# SN32F240 register map
Vendor: SONiX Technology Co., Ltd.; Series: SN32F200; File version: 2.0
CPU: CM0 r0p0, little endian, no MPU, no FPU, 2 interrupt priority bits
Registers are 32-bit, read-write, reset 0x0 unless marked. A register's access mark holds for its fields unless they carry their own. Offsets are from the block's base; [hi:lo] are bit positions; {n}, {i} and the like mark numbered series.

## SN_CT32B0 — 32-bit Timer 0 with Capture function
Base 0x40006000
Same registers: SN_CT32B1 0x40008000, SN_CT32B2 0x4000A000
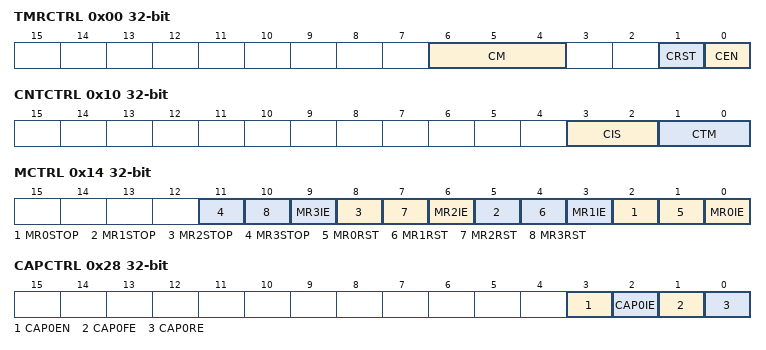
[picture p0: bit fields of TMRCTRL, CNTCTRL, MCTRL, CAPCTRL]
0x00 TMRCTRL — Offset:0x00 CT32Bn Timer Control Register
  [6:4] CM — Counting Mode
    0=Edge-aligned Up-counting mode; 1=Edge-aligned Down-counting mode; 2=Center-aligned mode 1 (The match interrupt flag is set during the down-counting period.); 4=Center-aligned mode 2 (The match interrupt flag is set during the up-counting period.); 6=Center-aligned mode 3 (The match interrupt flag is set during both up-counting and down-counting period.)
  [1] CRST — Counter Reset
    0=Disable; 1=Reset Counter (Timer Counter and the Prescale Counter are synchronously reset on the next positive edge of PCLK.)
  [0] CEN — Counter Enable
    0=Disable counter; 1=Enable Timer Counter and Prescale Counter for counting
0x04 TC — Offset:0x04 CT32Bn Timer Counter Register
0x08 PRE — Offset:0x08 CT32Bn Prescale Register
0x0C PC — Offset:0x0C CT32Bn Prescale Counter Register
0x10 CNTCTRL — Offset:0x10 CT32Bn Counter Control Register
  [3:2] CIS — Counter Input Select
    0=CT32Bn_CAP0 (Counter input from CT32Bn_CAP0)
  [1:0] CTM — Counter/Timer Mode
    0=Timer Mode (Every rising PCLK edge); 1=Counter Mode (TC is incremented on rising edges on the CAP0 input selected by CIS bits.); 2=Counter Mode (TC is incremented on falling edges on the CAP0 input selected by CIS bits.); 3=Counter Mode (TC is incremented on both edges on the CAP0 input selected by CIS bits.)
0x14 MCTRL — Offset:0x14 CT32Bn Match Control Register
  [3n+2] MR{n}STOP (n=0..3) — Stop TC and PC and clear CEN bit when MR{n} matches TC
    0=Disable; 1=Enable (Stop TC and PC and clear CEN bit when MR{n} matches TC)
  [3n+1] MR{n}RST (n=0..3) — Enable reset TC when MR{n} matches TC
    0=Disable; 1=Enable (Reset TC when MR{n} matches TC)
  [3n] MR{n}IE (n=0..3) — Enable generating an interrupt when MR{n} matches TC
    0=Disable; 1=Enable (Generating an interrupt when MR{n} matches TC)
{0x18+4i} MR{i} (i=0..3) — Offset:{0x18+4i} CT32Bn MR{i} Register
0x28 CAPCTRL — Offset:0x28 CT32Bn Capture Control Register
  [3] CAP0EN — CAP0 function enable
    0=Disable; 1=Enable CAP0 function
  [2] CAP0IE — Interrupt on CT32Bn_CAP0 event
    0=Disable; 1=Enable (A CAP0 load due to a CT32Bn_CAP0 event will generate an interrupt.)
  [1] CAP0FE — Capture on CT32Bn_CAP0 falling edge
    0=Disable; 1=Enable (A sequence of 1 then 0 on CT32Bn_CAP0 will cause CAP0 to be loaded with the contents of TC.)
  [0] CAP0RE — Capture on CT32Bn_CAP0 rising edge
    0=Disable; 1=Enable (A sequence of 0 then 1 on CT32Bn_CAP0 will cause CAP0 to be loaded with the contents of TC.)
0x2C CAP0 ro — Offset:0x2C CT32Bn CAP0 Register
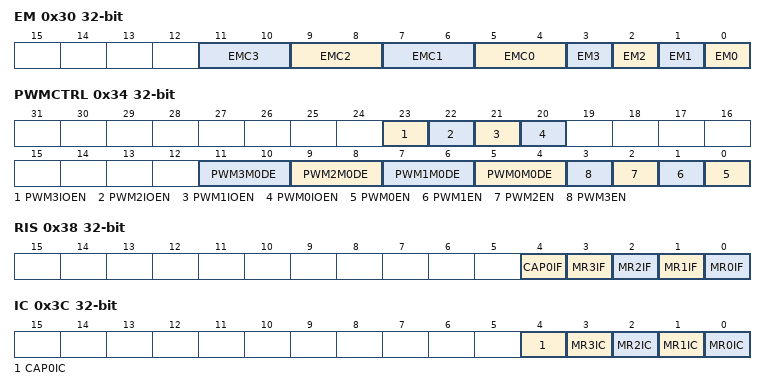
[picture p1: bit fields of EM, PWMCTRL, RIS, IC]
0x30 EM — Offset:0x30 CT32Bn External Match Register
  [2n+5:2n+4] EMC{n} (n=0..3) — CT32Bn_PWM{n} functionality
    0=Do Nothing; 1=Low (CT32Bn_PWM{n} pin is LOW); 2=High (CT32Bn_PWM{n} pin is HIGH); 3=Toggle CT32Bn_PWM{n} pin
  [n] EM{n} (n=0..3) — When the TC matches MR{n}, this bit will act according to EMC{n}[1:0], and also drive the state of CT32Bn_PWM{n} output.
0x34 PWMCTRL — Offset:0x34 CT32Bn PWM Control Register
  [23] PWM3IOEN — CT32Bn_PWM3/GPIO selection
    0=Disable (CT32Bn_PWM3 pin is act as GPIO); 1=Enable (CT32Bn_PWM3 pin act as match output, and output depends on PWM3EN bit)
  [22] PWM2IOEN — CT32Bn_PWM2/GPIO selection
    0=Disable (CT32Bn_PWM2 pin is act as GPIO); 1=Enable (CT32Bn_PWM2 pin act as match output, and output depends on PWM2EN bit)
  [21] PWM1IOEN — CT16Bn_PWM1/GPIO selection
    0=Disable (CT32Bn_PWM1 pin is act as GPIO); 1=Enable (CT32Bn_PWM1 pin act as match output, and output depends on PWM1EN bit)
  [20] PWM0IOEN — CT32Bn_PWM0/GPIO selection
    0=Disable (CT32Bn_PWM0 pin is act as GPIO); 1=Enable (CT32Bn_PWM0 pin act as match output, and output depends on PWM0EN bit)
  [2n+5:2n+4] PWM{n}M0DE (n=0..3) — PWM{n} output mode
    0=PWM mode 1 (During up-counting, PWM{n} is 0 when TC is less than MR{n}. During down-counting, PWM{n} is 1 when TC is larger/equal than MR{n}); 1=PWM mode 2 (During up-counting, PWM{n} is 1 when TC is less than MR{n}. During down-counting, PWM{n} is 0 when TC is larger/equal than MR{n}); 2=Force 0 (PWM{n} is forced to 0); 3=Force 1 (PWM{n} is forced to 1)
  [n] PWM{n}EN (n=0..3) — PWM{n} enable
    0=Disable (CT32Bn_PWM{n} is controlled by EM{n}); 1=Enable PWM mode for CT32Bn_PWM{n}
0x38 RIS ro — Offset:0x38 CT32Bn Raw Interrupt Status Register
  [4] CAP0IF — Capture channel 0 interrupt flag
    0=No (No interrupt on CAP0); 1=Met interrupt requirements (Interrupt requirements met on CAP0)
  [n] MR{n}IF (n=0..3) — Match channel {n} interrupt flag
    0=No (No interrupt on match channel {n}); 1=Met interrupt requirements (Interrupt requirements met on match channel {n})
0x3C IC wo — Offset:0x3C CT32Bn Interrupt Clear Register
  [4] CAP0IC — CAP0IF clear bit
    0=No effect; 1=Clear CAP0IF
  [n] MR{n}IC (n=0..3) — MR{n}IF clear bit
    0=No effect; 1=Clear MR{n}IF
